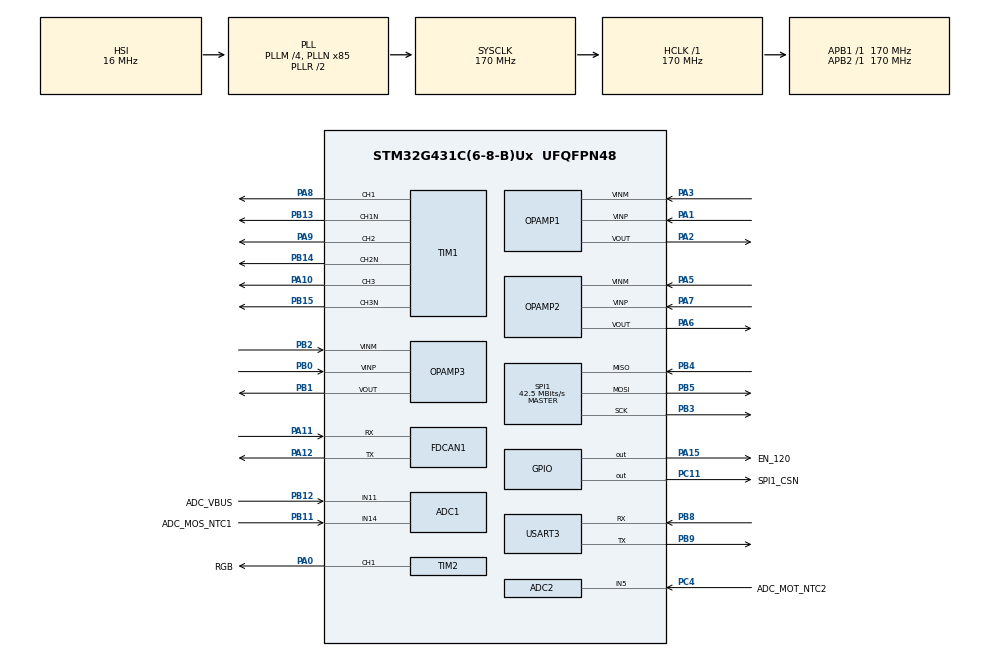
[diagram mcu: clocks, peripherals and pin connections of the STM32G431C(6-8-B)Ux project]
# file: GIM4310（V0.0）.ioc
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ADC1.Channel-0\#ChannelRegularConversion=ADC_CHANNEL_11
ADC1.NbrOfConversionFlag=1
ADC1.OffsetNumber-0\#ChannelRegularConversion=ADC_OFFSET_NONE
ADC1.Rank-0\#ChannelRegularConversion=1
ADC1.SamplingTime-0\#ChannelRegularConversion=ADC_SAMPLETIME_2CYCLES_5
ADC1.master=1
ADC2.Channel-0\#ChannelRegularConversion=ADC_CHANNEL_5
ADC2.NbrOfConversionFlag=1
ADC2.OffsetNumber-0\#ChannelRegularConversion=ADC_OFFSET_NONE
ADC2.Rank-0\#ChannelRegularConversion=1
ADC2.SamplingTime-0\#ChannelRegularConversion=ADC_SAMPLETIME_2CYCLES_5
FDCAN1.CalculateBaudRateNominal=3541666
FDCAN1.CalculateTimeBitNominal=282
FDCAN1.CalculateTimeQuantumNominal=94.11764705882354
Mcu.Family=STM32G4
Mcu.Name=STM32G431C(6-8-B)Ux
Mcu.Package=UFQFPN48
NVIC.PriorityGroup=NVIC_PRIORITYGROUP_4
PA0.GPIO_Label=RGB
PA0.Signal=S_TIM2_CH1
PA1.Mode=Standalone
PA1.Signal=OPAMP1_VINP
PA10.Signal=S_TIM1_CH3
PA11.Mode=FDCAN_Activate
PA11.Signal=FDCAN1_RX
PA12.Mode=FDCAN_Activate
PA12.Signal=FDCAN1_TX
PA13.Mode=Serial_Wire
PA13.Signal=SYS_JTMS-SWDIO
PA14.Mode=Serial_Wire
PA14.Signal=SYS_JTCK-SWCLK
PA15.GPIO_Label=EN_120
PA15.Signal=GPIO_Output
PA2.Mode=Standalone
PA2.Signal=OPAMP1_VOUT
PA3.Mode=Standalone
PA3.Signal=OPAMP1_VINM
PA5.Mode=Standalone
PA5.Signal=OPAMP2_VINM
PA6.Mode=Standalone
PA6.Signal=OPAMP2_VOUT
PA7.Mode=Standalone
PA7.Signal=OPAMP2_VINP
PA8.Signal=S_TIM1_CH1
PA9.Signal=S_TIM1_CH2
PB0.Mode=Standalone
PB0.Signal=OPAMP3_VINP
PB1.Mode=Standalone
PB1.Signal=OPAMP3_VOUT
PB11.GPIO_Label=ADC_MOS_NTC1
PB11.Mode=IN14-Single-Ended
PB11.Signal=ADC1_IN14
PB12.GPIO_Label=ADC_VBUS
PB12.Mode=IN11-Single-Ended
PB12.Signal=ADC1_IN11
PB13.Mode=PWM Generation1 CH1 CH1N
PB13.Signal=TIM1_CH1N
PB14.Mode=PWM Generation2 CH2 CH2N
PB14.Signal=TIM1_CH2N
PB15.Mode=PWM Generation3 CH3 CH3N
PB15.Signal=TIM1_CH3N
PB2.Mode=Standalone
PB2.Signal=OPAMP3_VINM
PB3.Mode=Full_Duplex_Master
PB3.Signal=SPI1_SCK
PB4.Mode=Full_Duplex_Master
PB4.Signal=SPI1_MISO
PB5.Mode=Full_Duplex_Master
PB5.Signal=SPI1_MOSI
PB8-BOOT0.Mode=Asynchronous
PB8-BOOT0.Signal=USART3_RX
PB9.Mode=Asynchronous
PB9.Signal=USART3_TX
PC11.GPIO_Label=SPI1_CSN
PC11.Signal=GPIO_Output
PC4.GPIO_Label=ADC_MOT_NTC2
PC4.Mode=IN5-Single-Ended
PC4.Signal=ADC2_IN5
PF0-OSC_IN.Mode=HSE-External-Oscillator
PF0-OSC_IN.Signal=RCC_OSC_IN
PF1-OSC_OUT.Mode=HSE-External-Oscillator
PF1-OSC_OUT.Signal=RCC_OSC_OUT
ProjectManager.HeapSize=0x200
ProjectManager.StackSize=0x400
ProjectManager.TargetToolchain=MDK-ARM V5.32
RCC.ADC12Freq_Value=170000000
RCC.AHBFreq_Value=170000000
RCC.APB1Freq_Value=170000000
RCC.APB1TimFreq_Value=170000000
RCC.APB2Freq_Value=170000000
RCC.APB2TimFreq_Value=170000000
RCC.CortexFreq_Value=170000000
RCC.EXTERNAL_CLOCK_VALUE=12288000
RCC.HCLKFreq_Value=170000000
RCC.HSE_VALUE=20000000
RCC.HSI48_VALUE=48000000
RCC.HSI_VALUE=16000000
RCC.LSE_VALUE=32768
RCC.PLLM=RCC_PLLM_DIV4
RCC.PLLN=85
RCC.SYSCLKFreq_VALUE=170000000
RCC.SYSCLKSource=RCC_SYSCLKSOURCE_PLLCLK
RCC.USBFreq_Value=170000000
RCC.VCOOutputFreq_Value=340000000
SH.S_TIM1_CH1.0=TIM1_CH1,PWM Generation1 CH1 CH1N
SH.S_TIM1_CH2.0=TIM1_CH2,PWM Generation2 CH2 CH2N
SH.S_TIM1_CH3.0=TIM1_CH3,PWM Generation3 CH3 CH3N
SH.S_TIM2_CH1.0=TIM2_CH1,PWM Generation1 CH1
SPI1.BaudRatePrescaler=SPI_BAUDRATEPRESCALER_4
SPI1.CalculateBaudRate=42.5 MBits/s
SPI1.Direction=SPI_DIRECTION_2LINES
SPI1.Mode=SPI_MODE_MASTER
SPI1.VirtualType=VM_MASTER
TIM1.Channel-PWM\ Generation1\ CH1\ CH1N=TIM_CHANNEL_1
TIM1.Channel-PWM\ Generation2\ CH2\ CH2N=TIM_CHANNEL_2
TIM1.Channel-PWM\ Generation3\ CH3\ CH3N=TIM_CHANNEL_3
TIM2.Channel-PWM\ Generation1\ CH1=TIM_CHANNEL_1
USART3.VirtualMode-Asynchronous=VM_ASYNC
VP_SYS_VS_DBSignals.Mode=DisableDeadBatterySignals
board=custom

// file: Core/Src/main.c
/* USER CODE BEGIN Header */
/**
  ******************************************************************************
  * @file           : main.c
  * @brief          : Main program body
  ******************************************************************************
  * @attention
  *
  * Copyright (c) 2026 STMicroelectronics.
  * All rights reserved.
  *
  * This software is licensed under terms that can be found in the LICENSE file
  * in the root directory of this software component.
  * If no LICENSE file comes with this software, it is provided AS-IS.
  *
  ******************************************************************************
  */
/* USER CODE END Header */
#include "main.h"
#include "adc.h"
#include "fdcan.h"
#include "opamp.h"
#include "spi.h"
#include "tim.h"
#include "usart.h"
#include "gpio.h"

/* USER CODE BEGIN Includes */
#include "app_main.h"
/* USER CODE END Includes */

void SystemClock_Config(void);

int main(void)
{

  /* MCU Configuration--------------------------------------------------------*/

  /* Reset of all peripherals, Initializes the Flash interface and the Systick. */
  HAL_Init();

  /* Configure the system clock */
  SystemClock_Config();

  /* Initialize all configured peripherals */
  MX_GPIO_Init();
  MX_ADC1_Init();
  MX_ADC2_Init();
  MX_FDCAN1_Init();
  MX_OPAMP1_Init();
  MX_OPAMP2_Init();
  MX_OPAMP3_Init();
  MX_SPI1_Init();
  MX_TIM1_Init();
  MX_TIM2_Init();
  MX_USART3_UART_Init();
  /* USER CODE BEGIN 2 */
  APP_Init();
  /* USER CODE END 2 */

  /* Infinite loop */
  while (1)
  {

    /* USER CODE BEGIN 3 */
    APP_Loop();
  }
  /* USER CODE END 3 */
}

void SystemClock_Config(void)
{
  RCC_OscInitTypeDef RCC_OscInitStruct = {0};
  RCC_ClkInitTypeDef RCC_ClkInitStruct = {0};

  /** Configure the main internal regulator output voltage
  */
  HAL_PWREx_ControlVoltageScaling(PWR_REGULATOR_VOLTAGE_SCALE1_BOOST);

  /** Initializes the RCC Oscillators according to the specified parameters
  * in the RCC_OscInitTypeDef structure.
  */
  RCC_OscInitStruct.OscillatorType = RCC_OSCILLATORTYPE_HSI;
  RCC_OscInitStruct.HSIState = RCC_HSI_ON;
  RCC_OscInitStruct.HSICalibrationValue = RCC_HSICALIBRATION_DEFAULT;
  RCC_OscInitStruct.PLL.PLLState = RCC_PLL_ON;
  RCC_OscInitStruct.PLL.PLLSource = RCC_PLLSOURCE_HSI;
  RCC_OscInitStruct.PLL.PLLM = RCC_PLLM_DIV4;
  RCC_OscInitStruct.PLL.PLLN = 85;
  RCC_OscInitStruct.PLL.PLLP = RCC_PLLP_DIV2;
  RCC_OscInitStruct.PLL.PLLQ = RCC_PLLQ_DIV2;
  RCC_OscInitStruct.PLL.PLLR = RCC_PLLR_DIV2;
  if (HAL_RCC_OscConfig(&RCC_OscInitStruct) != HAL_OK)
  {
    Error_Handler();
  }

  /** Initializes the CPU, AHB and APB buses clocks
  */
  RCC_ClkInitStruct.ClockType = RCC_CLOCKTYPE_HCLK|RCC_CLOCKTYPE_SYSCLK
                              |RCC_CLOCKTYPE_PCLK1|RCC_CLOCKTYPE_PCLK2;
  RCC_ClkInitStruct.SYSCLKSource = RCC_SYSCLKSOURCE_PLLCLK;
  RCC_ClkInitStruct.AHBCLKDivider = RCC_SYSCLK_DIV1;
  RCC_ClkInitStruct.APB1CLKDivider = RCC_HCLK_DIV1;
  RCC_ClkInitStruct.APB2CLKDivider = RCC_HCLK_DIV1;

  if (HAL_RCC_ClockConfig(&RCC_ClkInitStruct, FLASH_LATENCY_4) != HAL_OK)
  {
    Error_Handler();
  }
}

void Error_Handler(void)
{
  /* USER CODE BEGIN Error_Handler_Debug */
  /* 先封波再停机：清 TIM1 MOE，输出高阻，FD6288 内部下拉关断三相 */
  TIM1->BDTR &= ~TIM_BDTR_MOE;
  __disable_irq();
  while (1)
  {
  }
  /* USER CODE END Error_Handler_Debug */
}
